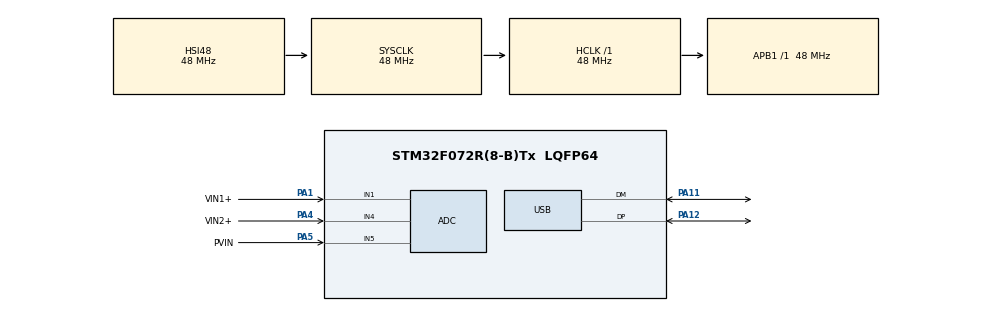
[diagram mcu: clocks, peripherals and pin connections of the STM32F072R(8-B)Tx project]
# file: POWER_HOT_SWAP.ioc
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ADC.ContinuousConvMode=ENABLE
Dma.ADC.0.Direction=DMA_PERIPH_TO_MEMORY
Dma.ADC.0.Instance=DMA1_Channel1
Dma.ADC.0.MemDataAlignment=DMA_MDATAALIGN_HALFWORD
Dma.ADC.0.MemInc=DMA_MINC_ENABLE
Dma.ADC.0.Mode=DMA_CIRCULAR
Dma.ADC.0.PeriphDataAlignment=DMA_PDATAALIGN_HALFWORD
Dma.ADC.0.PeriphInc=DMA_PINC_DISABLE
Dma.ADC.0.Priority=DMA_PRIORITY_HIGH
Dma.Request0=ADC
Mcu.Family=STM32F0
Mcu.Name=STM32F072R(8-B)Tx
Mcu.Package=LQFP64
NVIC.DMA1_Channel1_IRQn=true\:0\:0\:false\:false\:true\:false\:true
NVIC.USB_IRQn=true\:0\:0\:false\:false\:true\:false\:true
PA1.GPIO_Label=VIN1+
PA1.Mode=IN1
PA1.Signal=ADC_IN1
PA11.Mode=Device
PA11.Signal=USB_DM
PA12.Mode=Device
PA12.Signal=USB_DP
PA13.Mode=Serial_Wire
PA13.Signal=SYS_SWDIO
PA14.Mode=Serial_Wire
PA14.Signal=SYS_SWCLK
PA4.GPIO_Label=VIN2+
PA4.Mode=IN4
PA4.Signal=ADC_IN4
PA5.GPIO_Label=PVIN
PA5.Mode=IN5
PA5.Signal=ADC_IN5
PF0-OSC_IN.Mode=HSE-External-Oscillator
PF0-OSC_IN.Signal=RCC_OSC_IN
PF1-OSC_OUT.Mode=HSE-External-Oscillator
PF1-OSC_OUT.Signal=RCC_OSC_OUT
ProjectManager.HeapSize=0x200
ProjectManager.StackSize=0x400
ProjectManager.TargetToolchain=EWARM V8.32
RCC.AHBFreq_Value=48000000
RCC.APB1Freq_Value=48000000
RCC.APB1TimFreq_Value=48000000
RCC.HCLKFreq_Value=48000000
RCC.PLLSourceVirtual=RCC_PLLSOURCE_HSE
RCC.SYSCLKFreq_VALUE=48000000
RCC.SYSCLKSource=RCC_SYSCLKSOURCE_HSI48
USB_DEVICE.CLASS_NAME_FS=CDC
USB_DEVICE.VirtualMode=Cdc
USB_DEVICE.VirtualModeFS=Cdc_FS
VP_USB_DEVICE_VS_USB_DEVICE_CDC_FS.Mode=CDC_FS
board=custom

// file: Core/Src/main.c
/* USER CODE BEGIN Header */
/**
  ******************************************************************************
  * @file           : main.c
  * @brief          : Main program body
  ******************************************************************************
  * @attention
  *
  * <h2><center>&copy; Copyright (c) 2021 STMicroelectronics.
  * All rights reserved.</center></h2>
  *
  * This software component is licensed by ST under BSD 3-Clause license,
  * the "License"; You may not use this file except in compliance with the
  * License. You may obtain a copy of the License at:
  *                        opensource.org/licenses/BSD-3-Clause
  *
  ******************************************************************************
  */
/* USER CODE END Header */
#include "main.h"
#include "adc.h"
#include "dma.h"
#include "usb_device.h"
#include "gpio.h"

void SystemClock_Config(void);

int main(void)
{

  /* MCU Configuration--------------------------------------------------------*/

  /* Reset of all peripherals, Initializes the Flash interface and the Systick. */
  HAL_Init();

  /* Configure the system clock */
  SystemClock_Config();

  /* Initialize all configured peripherals */
  MX_GPIO_Init();
  MX_DMA_Init();
  MX_USB_DEVICE_Init();
  MX_ADC_Init();
  /* USER CODE BEGIN 2 */

	HAL_ADC_Start_DMA

  /* USER CODE END 2 */

  /* Infinite loop */
  while (1)
  {

  }
}

void SystemClock_Config(void)
{
  RCC_OscInitTypeDef RCC_OscInitStruct = {0};
  RCC_ClkInitTypeDef RCC_ClkInitStruct = {0};
  RCC_PeriphCLKInitTypeDef PeriphClkInit = {0};

  /** Initializes the RCC Oscillators according to the specified parameters
  * in the RCC_OscInitTypeDef structure.
  */
  RCC_OscInitStruct.OscillatorType = RCC_OSCILLATORTYPE_HSI14|RCC_OSCILLATORTYPE_HSI48;
  RCC_OscInitStruct.HSI48State = RCC_HSI48_ON;
  RCC_OscInitStruct.HSI14State = RCC_HSI14_ON;
  RCC_OscInitStruct.HSI14CalibrationValue = 16;
  RCC_OscInitStruct.PLL.PLLState = RCC_PLL_NONE;
  if (HAL_RCC_OscConfig(&RCC_OscInitStruct) != HAL_OK)
  {
    Error_Handler();
  }
  /** Initializes the CPU, AHB and APB buses clocks
  */
  RCC_ClkInitStruct.ClockType = RCC_CLOCKTYPE_HCLK|RCC_CLOCKTYPE_SYSCLK
                              |RCC_CLOCKTYPE_PCLK1;
  RCC_ClkInitStruct.SYSCLKSource = RCC_SYSCLKSOURCE_HSI48;
  RCC_ClkInitStruct.AHBCLKDivider = RCC_SYSCLK_DIV1;
  RCC_ClkInitStruct.APB1CLKDivider = RCC_HCLK_DIV1;

  if (HAL_RCC_ClockConfig(&RCC_ClkInitStruct, FLASH_LATENCY_1) != HAL_OK)
  {
    Error_Handler();
  }
  PeriphClkInit.PeriphClockSelection = RCC_PERIPHCLK_USB;
  PeriphClkInit.UsbClockSelection = RCC_USBCLKSOURCE_HSI48;

  if (HAL_RCCEx_PeriphCLKConfig(&PeriphClkInit) != HAL_OK)
  {
    Error_Handler();
  }
}

void Error_Handler(void)
{
  __disable_irq();
  while (1)
  {
  }
}

/************************ (C) COPYRIGHT STMicroelectronics *****END OF FILE****/
